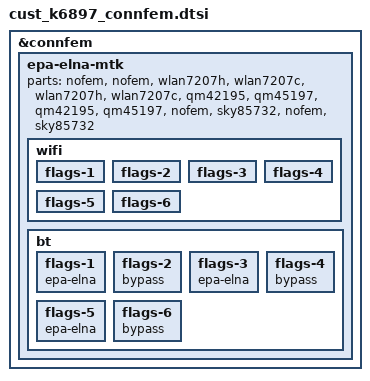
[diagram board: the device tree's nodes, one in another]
// SPDX-License-Identifier: (GPL-2.0 OR MIT)
/*
 * Copyright (C) 2020 MediaTek Inc.
 */
&connfem {
	epa-elna-mtk {
		parts = <&nofem &nofem>,		/* [0]iPA/iLNA */
			<&wlan7207h &wlan7207c>,	/* [1]NXP eFEM - Closed-Loop */
			<&wlan7207h &wlan7207c>,	/* [2]NXP eFEM - Closed-Loop+BT Bypass */
			<&qm42195 &qm45197>,		/* [3]Qorvo eFEM - Closed-Loop */
			<&qm42195 &qm45197>,		/* [4]Qorvo eFEM - Closed-Loop+BT Bypass */
			<&nofem &sky85732>,		/* [5]Skyworks eFEM - Closed-Loop */
			<&nofem &sky85732>;		/* [6]Skyworks eFEM - Closed-Loop+BT Bypass */

		wifi {
			flags-1 {
				/* open-loop; */
			};
			flags-2 {
				/* open-loop; */
			};
			flags-3 {
				/* open-loop; */
			};
			flags-4 {
				/* open-loop; */
			};
			flags-5 {
				/* open-loop; */
			};
			flags-6 {
				/* open-loop; */
			};
		};
		bt {
			flags-1 {
				/* choose one of: epa-elna / epa / elna / bypass */
				epa-elna;
			};
			flags-2 {
				/* choose one of: epa-elna / epa / elna / bypass */
				bypass;
			};
			flags-3 {
				/* choose one of: epa-elna / epa / elna / bypass */
				epa-elna;
			};
			flags-4 {
				/* choose one of: epa-elna / epa / elna / bypass */
				bypass;
			};
			flags-5 {
				/* choose one of: epa-elna / epa / elna / bypass */
				epa-elna;
			};
			flags-6 {
				/* choose one of: epa-elna / epa / elna / bypass */
				bypass;
			};
		};
	};
};
